# N32H7xx register map
Vendor: Nationstech Ltd.; File version: 1.0
CPU: CM7 r1p1, little endian, MPU, FPU, 4 interrupt priority bits
Registers are 32-bit, read-write, reset 0x0 unless marked. A register's access mark holds for its fields unless they carry their own. Offsets are from the block's base; [hi:lo] are bit positions; {n}, {i} and the like mark numbered series.

## AFIO — Alternate Function I/O
Base 0x58032400
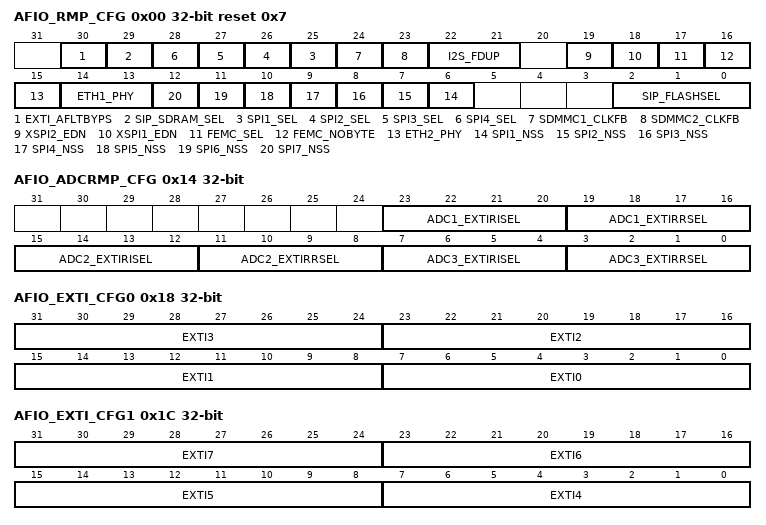
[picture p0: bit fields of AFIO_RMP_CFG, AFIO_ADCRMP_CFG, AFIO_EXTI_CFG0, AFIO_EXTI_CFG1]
0x00 AFIO_RMP_CFG reset 0x7 — Mapping configurations
  [30] EXTI_AFLTBYPS, [29] SIP_SDRAM_SEL, [n+24] SPI{n}_SEL (n=1..4), [24] SDMMC1_CLKFB, [23] SDMMC2_CLKFB, [22:21] I2S_FDUP, [19] XSPI2_EDN, [18] XSPI1_EDN, [17] FEMC_SEL, [16] FEMC_NOBYTE, [15] ETH2_PHY, [14:13] ETH1_PHY, [n+5] SPI{n}_NSS (n=1..7), [2:0] SIP_FLASHSEL
0x04 AFIO_FILTER_CFG — IOM_FILT
  [6:0] IOFLITCFG
0x08 AFIO_XSPI1_NON0 reset 0xA54B885C — Xspi_dec_nonce
  [31:0] XSPI1_DEC_NONCE0
0x0C AFIO_XSPI1_NON1 reset 0xDC0 — Xspi_dec_nonce
  [31:0] XSPI1_DEC_NONCE1
0x10 AFIO_XSPI1_NON2 — Xspi_dec_nonce
  [31:0] XSPI1_DEC_NONCE2
0x14 AFIO_ADCRMP_CFG — ADC_ETRG
  [23:20] ADC1_EXTIRISEL, [19:16] ADC1_EXTIRRSEL, [15:12] ADC2_EXTIRISEL, [11:8] ADC2_EXTIRRSEL, [7:4] ADC3_EXTIRISEL, [3:0] ADC3_EXTIRRSEL
0x18 AFIO_EXTI_CFG0 — EXTI line configuration (0-3)
  [8n+7:8n] EXTI{n} (n=0..3)
0x1C AFIO_EXTI_CFG1 — EXTI line configuration (4-7)
  [8n-25:8n-32] EXTI{n} (n=4..7)
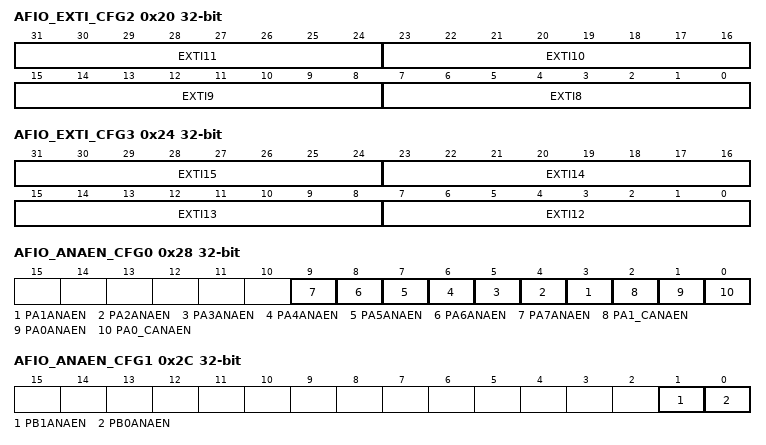
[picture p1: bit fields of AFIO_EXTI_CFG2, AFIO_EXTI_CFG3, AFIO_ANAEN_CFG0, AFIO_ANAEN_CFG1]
0x20 AFIO_EXTI_CFG2 — EXTI line configuration (8-11)
  [8n-57:8n-64] EXTI{n} (n=8..11)
0x24 AFIO_EXTI_CFG3 — EXTI line configuration (12-15)
  [8n-89:8n-96] EXTI{n} (n=12..15)
0x28 AFIO_ANAEN_CFG0 — GPIOA Analog Signal Channel Config
  [n+2] PA{n}ANAEN (n=1..7), [2] PA1_CANAEN, [1] PA0ANAEN, [0] PA0_CANAEN
0x2C AFIO_ANAEN_CFG1 — GPIOB Analog Signal Channel Config
  [1] PB1ANAEN, [0] PB0ANAEN
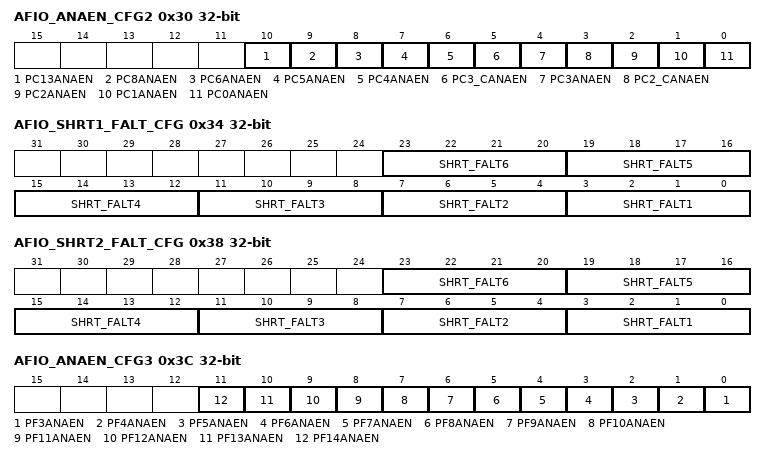
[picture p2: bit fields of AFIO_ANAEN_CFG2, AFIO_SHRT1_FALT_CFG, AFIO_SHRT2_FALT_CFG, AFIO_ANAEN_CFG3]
0x30 AFIO_ANAEN_CFG2 — GPIOC Analog Signal Channel Config
  [10] PC13ANAEN, [9] PC8ANAEN, [8] PC6ANAEN, [7] PC5ANAEN, [6] PC4ANAEN, [5] PC3_CANAEN, [4] PC3ANAEN, [3] PC2_CANAEN, [2] PC2ANAEN, [1] PC1ANAEN, [0] PC0ANAEN
0x34 AFIO_SHRT1_FALT_CFG — SHRTIM1_FLT
  [4n-1:4n-4] SHRT_FALT{n} (n=1..6)
0x38 AFIO_SHRT2_FALT_CFG — SHRTIM2_FLT
  [4n-1:4n-4] SHRT_FALT{n} (n=1..6)
0x3C AFIO_ANAEN_CFG3 — GPIOF Analog Signal Channel Config
  [n-3] PF{n}ANAEN (n=3..14)
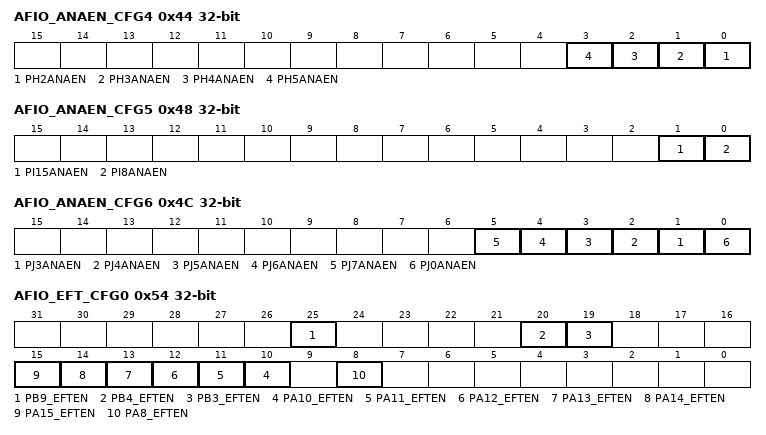
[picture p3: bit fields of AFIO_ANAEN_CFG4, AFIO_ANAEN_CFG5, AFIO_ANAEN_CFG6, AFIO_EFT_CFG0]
0x44 AFIO_ANAEN_CFG4 — GPIOH Analog Signal Channel Config
  [n-2] PH{n}ANAEN (n=2..5)
0x48 AFIO_ANAEN_CFG5 — GPIOI Analog Signal Channel Config
  [1] PI15ANAEN, [0] PI8ANAEN
0x4C AFIO_ANAEN_CFG6 — GPIOJ Analog Signal Channel Config
  [n-2] PJ{n}ANAEN (n=3..7), [0] PJ0ANAEN
0x54 AFIO_EFT_CFG0 — AB_EFTIE
  [25] PB9_EFTEN, [20] PB4_EFTEN, [19] PB3_EFTEN, [n] PA{n}_EFTEN (n=10..15), [8] PA8_EFTEN
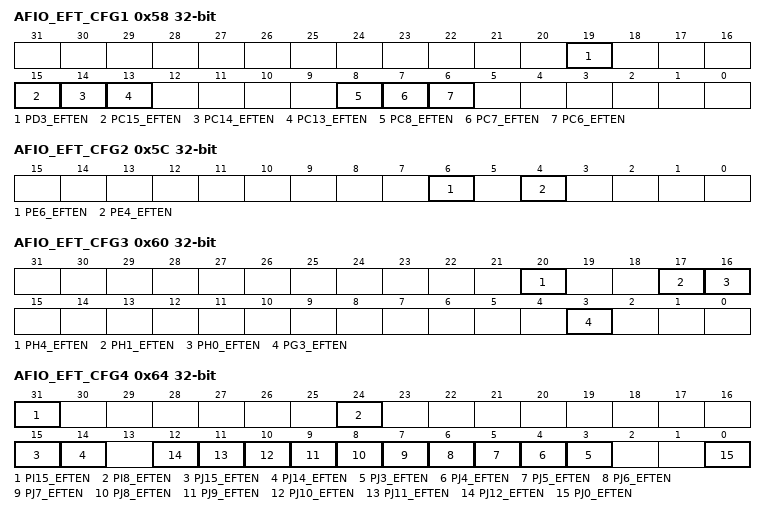
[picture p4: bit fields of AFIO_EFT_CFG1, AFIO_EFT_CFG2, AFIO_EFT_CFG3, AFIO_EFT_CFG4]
0x58 AFIO_EFT_CFG1 — CD_EFTIE
  [19] PD3_EFTEN, [15] PC15_EFTEN, [14] PC14_EFTEN, [13] PC13_EFTEN, [8] PC8_EFTEN, [7] PC7_EFTEN, [6] PC6_EFTEN
0x5C AFIO_EFT_CFG2 — EF_EFTIE
  [6] PE6_EFTEN, [4] PE4_EFTEN
0x60 AFIO_EFT_CFG3 — GH_EFTIE
  [20] PH4_EFTEN, [17] PH1_EFTEN, [16] PH0_EFTEN, [3] PG3_EFTEN
0x64 AFIO_EFT_CFG4 — IJ_EFTIE
  [31] PI15_EFTEN, [24] PI8_EFTEN, [15] PJ15_EFTEN, [14] PJ14_EFTEN, [n] PJ{n}_EFTEN (n=3..12), [0] PJ0_EFTEN
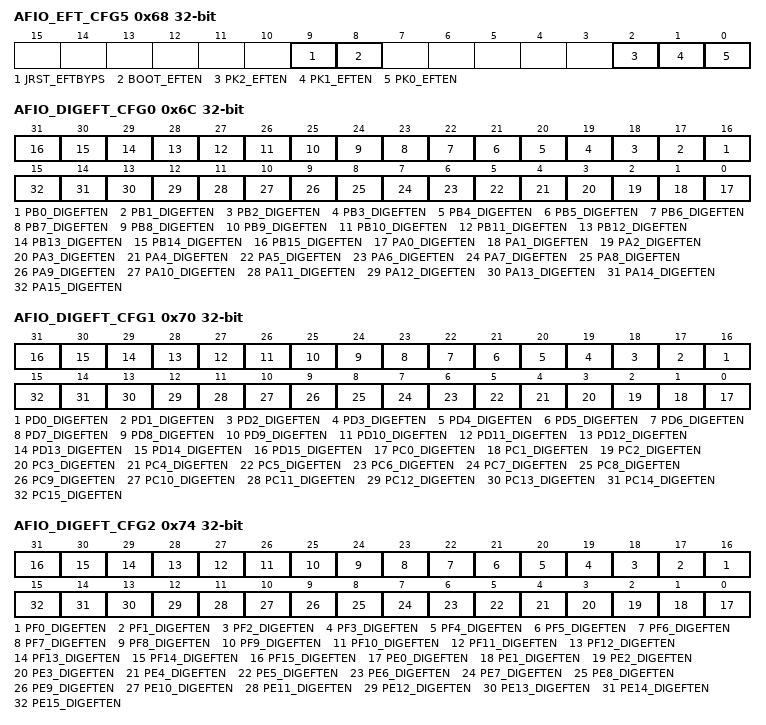
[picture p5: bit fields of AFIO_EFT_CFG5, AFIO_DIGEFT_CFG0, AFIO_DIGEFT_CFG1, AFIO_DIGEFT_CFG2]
0x68 AFIO_EFT_CFG5 — K_EFTIE
  [9] JRST_EFTBYPS, [8] BOOT_EFTEN, [2] PK2_EFTEN, [1] PK1_EFTEN, [0] PK0_EFTEN
0x6C AFIO_DIGEFT_CFG0 — AB_ DigitalEFTIE
  [n+16] PB{n}_DIGEFTEN (n=0..15), [n] PA{n}_DIGEFTEN (n=0..15)
0x70 AFIO_DIGEFT_CFG1 — CD_ DigitalEFTIE
  [n+16] PD{n}_DIGEFTEN (n=0..15), [n] PC{n}_DIGEFTEN (n=0..15)
0x74 AFIO_DIGEFT_CFG2 — EF_ DigitalEFTIE
  [n+16] PF{n}_DIGEFTEN (n=0..15), [n] PE{n}_DIGEFTEN (n=0..15)
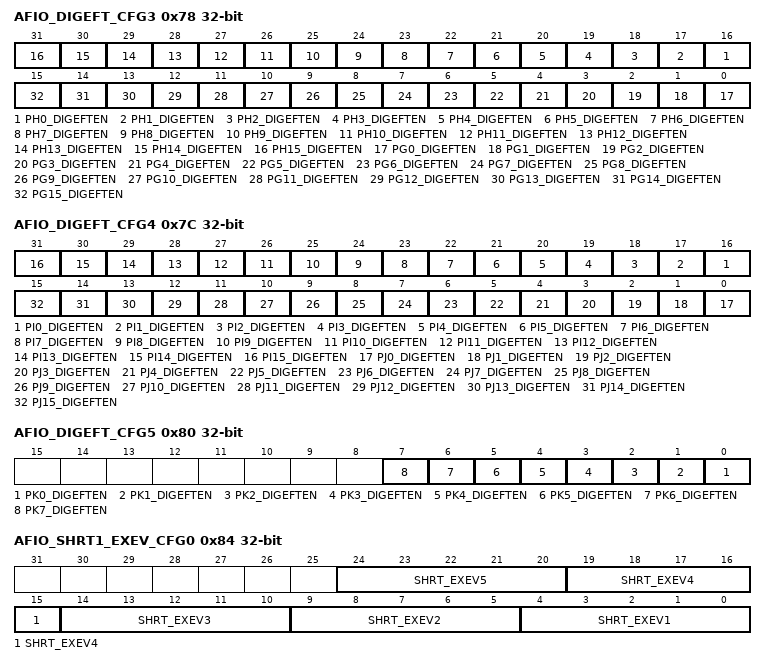
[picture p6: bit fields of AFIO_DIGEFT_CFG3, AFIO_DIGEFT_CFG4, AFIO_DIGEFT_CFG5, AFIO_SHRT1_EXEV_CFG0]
0x78 AFIO_DIGEFT_CFG3 — GH_ DigitalEFTIE
  [n+16] PH{n}_DIGEFTEN (n=0..15), [n] PG{n}_DIGEFTEN (n=0..15)
0x7C AFIO_DIGEFT_CFG4 — IJ_ DigitalEFTIE
  [n+16] PI{n}_DIGEFTEN (n=0..15), [n] PJ{n}_DIGEFTEN (n=0..15)
0x80 AFIO_DIGEFT_CFG5 — K_ DigitalEFTIE
  [n] PK{n}_DIGEFTEN (n=0..7)
0x84 AFIO_SHRT1_EXEV_CFG0 — SHRT_EXEV1
  [5n-1:5n-5] SHRT_EXEV{n} (n=1..5)
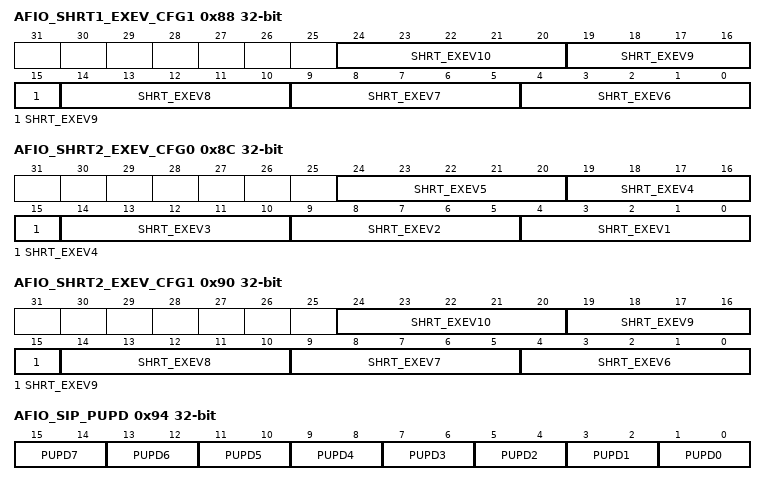
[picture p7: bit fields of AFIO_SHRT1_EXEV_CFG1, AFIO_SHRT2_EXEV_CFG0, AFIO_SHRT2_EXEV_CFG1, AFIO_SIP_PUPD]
0x88 AFIO_SHRT1_EXEV_CFG1 — SHRT_EXEV2
  [5n-26:5n-30] SHRT_EXEV{n} (n=6..10)
0x8C AFIO_SHRT2_EXEV_CFG0 — SHRT_EXEV3
  [5n-1:5n-5] SHRT_EXEV{n} (n=1..5)
0x90 AFIO_SHRT2_EXEV_CFG1 — SHRT_EXEV4
  [5n-26:5n-30] SHRT_EXEV{n} (n=6..10)
0x94 AFIO_SIP_PUPD — SIP_PULL_UP_DOWN
  [2n+1:2n] PUPD{n} (n=0..7)
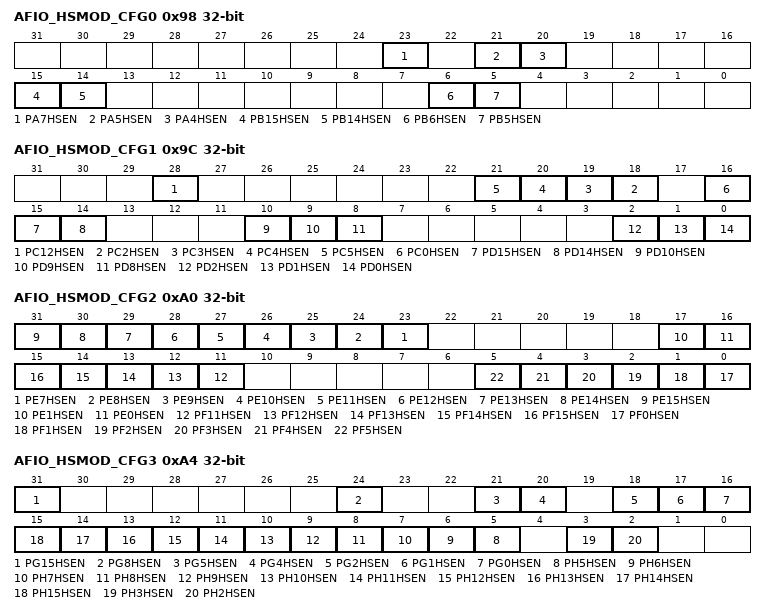
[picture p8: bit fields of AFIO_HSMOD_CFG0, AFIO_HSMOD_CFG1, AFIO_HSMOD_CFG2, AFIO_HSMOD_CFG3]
0x98 AFIO_HSMOD_CFG0 — AB_HSMODE
  [23] PA7HSEN, [21] PA5HSEN, [20] PA4HSEN, [15] PB15HSEN, [14] PB14HSEN, [6] PB6HSEN, [5] PB5HSEN
0x9C AFIO_HSMOD_CFG1 — CD_HSMODE
  [28] PC12HSEN, [n+16] PC{n}HSEN (n=2..5), [16] PC0HSEN, [15] PD15HSEN, [14] PD14HSEN, [10] PD10HSEN, [9] PD9HSEN, [8] PD8HSEN, [2] PD2HSEN, [1] PD1HSEN, [0] PD0HSEN
0xA0 AFIO_HSMOD_CFG2 — EF_HSMODE
  [n+16] PE{n}HSEN (n=7..15), [17] PE1HSEN, [16] PE0HSEN, [n] PF{n}HSEN (n=11..15), [n] PF{n}HSEN (n=0..5)
0xA4 AFIO_HSMOD_CFG3 — GH_HSMODE
  [31] PG15HSEN, [24] PG8HSEN, [21] PG5HSEN, [20] PG4HSEN, [18] PG2HSEN, [17] PG1HSEN, [16] PG0HSEN, [n] PH{n}HSEN (n=5..15), [3] PH3HSEN, [2] PH2HSEN
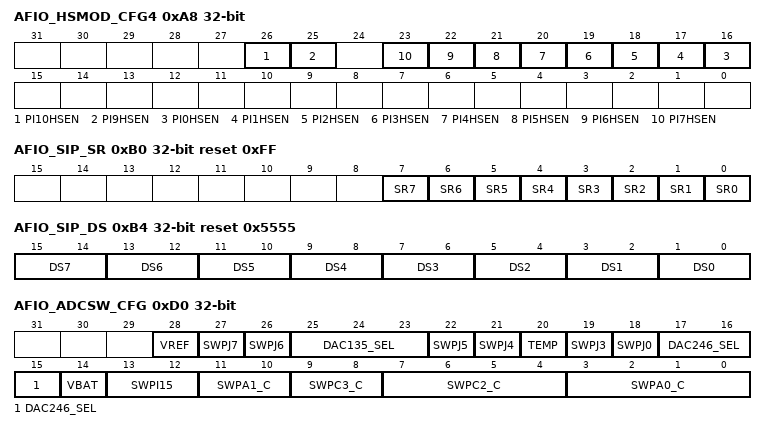
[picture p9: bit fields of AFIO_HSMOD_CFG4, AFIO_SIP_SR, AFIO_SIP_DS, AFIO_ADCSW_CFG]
0xA8 AFIO_HSMOD_CFG4 — I_HSMODE
  [26] PI10HSEN, [25] PI9HSEN, [n+16] PI{n}HSEN (n=0..7)
0xB0 AFIO_SIP_SR reset 0xFF — SIPSR
  [n] SR{n} (n=0..7)
0xB4 AFIO_SIP_DS reset 0x5555 — SIPDS
  [2n+1:2n] DS{n} (n=0..7)
0xD0 AFIO_ADCSW_CFG — ADCSW
  [28] VREF, [27] SWPJ7, [26] SWPJ6, [25:23] DAC135_SEL, [22] SWPJ5, [21] SWPJ4, [20] TEMP, [19] SWPJ3, [18] SWPJ0, [17:15] DAC246_SEL, [14] VBAT, [13:12] SWPI15, [11:10] SWPA1_C, [9:8] SWPC3_C, [7:4] SWPC2_C, [3:0] SWPA0_C
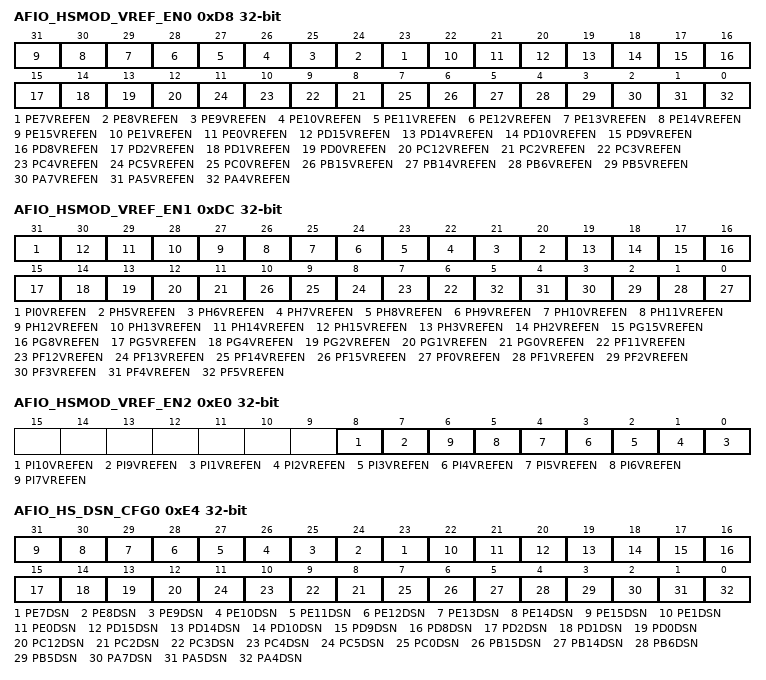
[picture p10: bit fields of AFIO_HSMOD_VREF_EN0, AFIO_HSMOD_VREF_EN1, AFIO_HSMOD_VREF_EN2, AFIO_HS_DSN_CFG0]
0xD8 AFIO_HSMOD_VREF_EN0 — IO Port High Speed Mode VREF Enable0
  [n+16] PE{n}VREFEN (n=7..15), [22] PE1VREFEN, [21] PE0VREFEN, [20] PD15VREFEN, [19] PD14VREFEN, [18] PD10VREFEN, [17] PD9VREFEN, [16] PD8VREFEN, [15] PD2VREFEN, [14] PD1VREFEN, [13] PD0VREFEN, [12] PC12VREFEN, [n+6] PC{n}VREFEN (n=2..5), [7] PC0VREFEN, [6] PB15VREFEN, [5] PB14VREFEN, [4] PB6VREFEN, [3] PB5VREFEN, [2] PA7VREFEN, [1] PA5VREFEN, [0] PA4VREFEN
0xDC AFIO_HSMOD_VREF_EN1 — IO Port High Speed Mode VREF Enable1
  [31] PI0VREFEN, [n+15] PH{n}VREFEN (n=5..15), [19] PH3VREFEN, [18] PH2VREFEN, [17] PG15VREFEN, [16] PG8VREFEN, [15] PG5VREFEN, [14] PG4VREFEN, [13] PG2VREFEN, [12] PG1VREFEN, [11] PG0VREFEN, [n-5] PF{n}VREFEN (n=11..15), [n] PF{n}VREFEN (n=0..5)
0xE0 AFIO_HSMOD_VREF_EN2 — IO Port High Speed Mode VREF Enable2
  [8] PI10VREFEN, [7] PI9VREFEN, [n-1] PI{n}VREFEN (n=1..7)
0xE4 AFIO_HS_DSN_CFG0 — High Speed IO Port DSN CFG0
  [n+16] PE{n}DSN (n=7..15), [22] PE1DSN, [21] PE0DSN, [20] PD15DSN, [19] PD14DSN, [18] PD10DSN, [17] PD9DSN, [16] PD8DSN, [15] PD2DSN, [14] PD1DSN, [13] PD0DSN, [12] PC12DSN, [n+6] PC{n}DSN (n=2..5), [7] PC0DSN, [6] PB15DSN, [5] PB14DSN, [4] PB6DSN, [3] PB5DSN, [2] PA7DSN, [1] PA5DSN, [0] PA4DSN
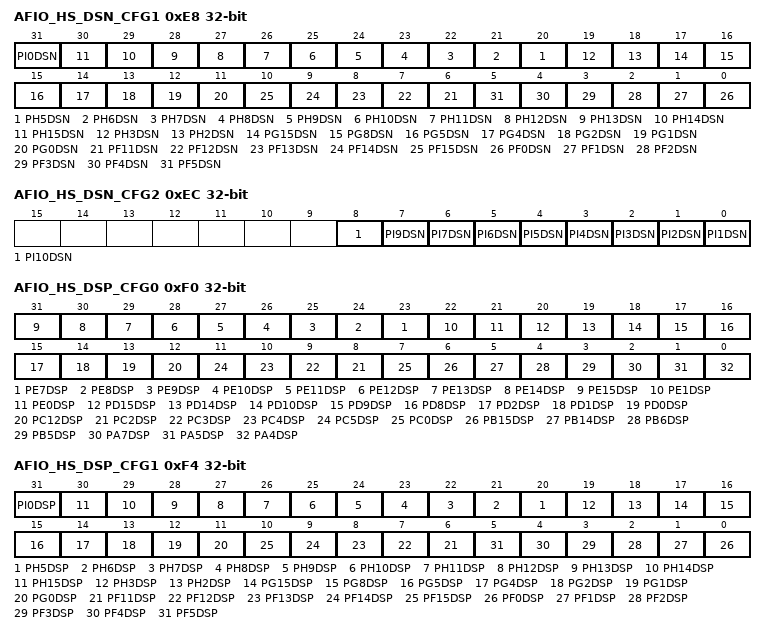
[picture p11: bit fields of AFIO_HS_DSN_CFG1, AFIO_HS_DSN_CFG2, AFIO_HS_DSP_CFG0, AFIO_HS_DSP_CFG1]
0xE8 AFIO_HS_DSN_CFG1 — High Speed IO Port DSN CFG1
  [31] PI0DSN, [n+15] PH{n}DSN (n=5..15), [19] PH3DSN, [18] PH2DSN, [17] PG15DSN, [16] PG8DSN, [15] PG5DSN, [14] PG4DSN, [13] PG2DSN, [12] PG1DSN, [11] PG0DSN, [n-5] PF{n}DSN (n=11..15), [n] PF{n}DSN (n=0..5)
0xEC AFIO_HS_DSN_CFG2 — High Speed IO Port DSN CFG2
  [8] PI10DSN, [7] PI9DSN, [n-1] PI{n}DSN (n=1..7)
0xF0 AFIO_HS_DSP_CFG0 — High Speed IO Port DSP CFG0
  [n+16] PE{n}DSP (n=7..15), [22] PE1DSP, [21] PE0DSP, [20] PD15DSP, [19] PD14DSP, [18] PD10DSP, [17] PD9DSP, [16] PD8DSP, [15] PD2DSP, [14] PD1DSP, [13] PD0DSP, [12] PC12DSP, [n+6] PC{n}DSP (n=2..5), [7] PC0DSP, [6] PB15DSP, [5] PB14DSP, [4] PB6DSP, [3] PB5DSP, [2] PA7DSP, [1] PA5DSP, [0] PA4DSP
0xF4 AFIO_HS_DSP_CFG1 — High Speed IO Port DSP CFG1
  [31] PI0DSP, [n+15] PH{n}DSP (n=5..15), [19] PH3DSP, [18] PH2DSP, [17] PG15DSP, [16] PG8DSP, [15] PG5DSP, [14] PG4DSP, [13] PG2DSP, [12] PG1DSP, [11] PG0DSP, [n-5] PF{n}DSP (n=11..15), [n] PF{n}DSP (n=0..5)
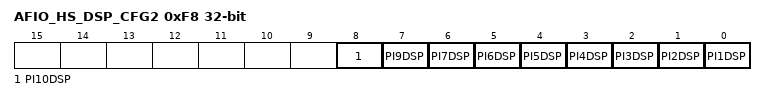
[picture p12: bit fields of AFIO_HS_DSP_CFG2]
0xF8 AFIO_HS_DSP_CFG2 — High Speed IO Port DSP CFG2
  [8] PI10DSP, [7] PI9DSP, [n-1] PI{n}DSP (n=1..7)
